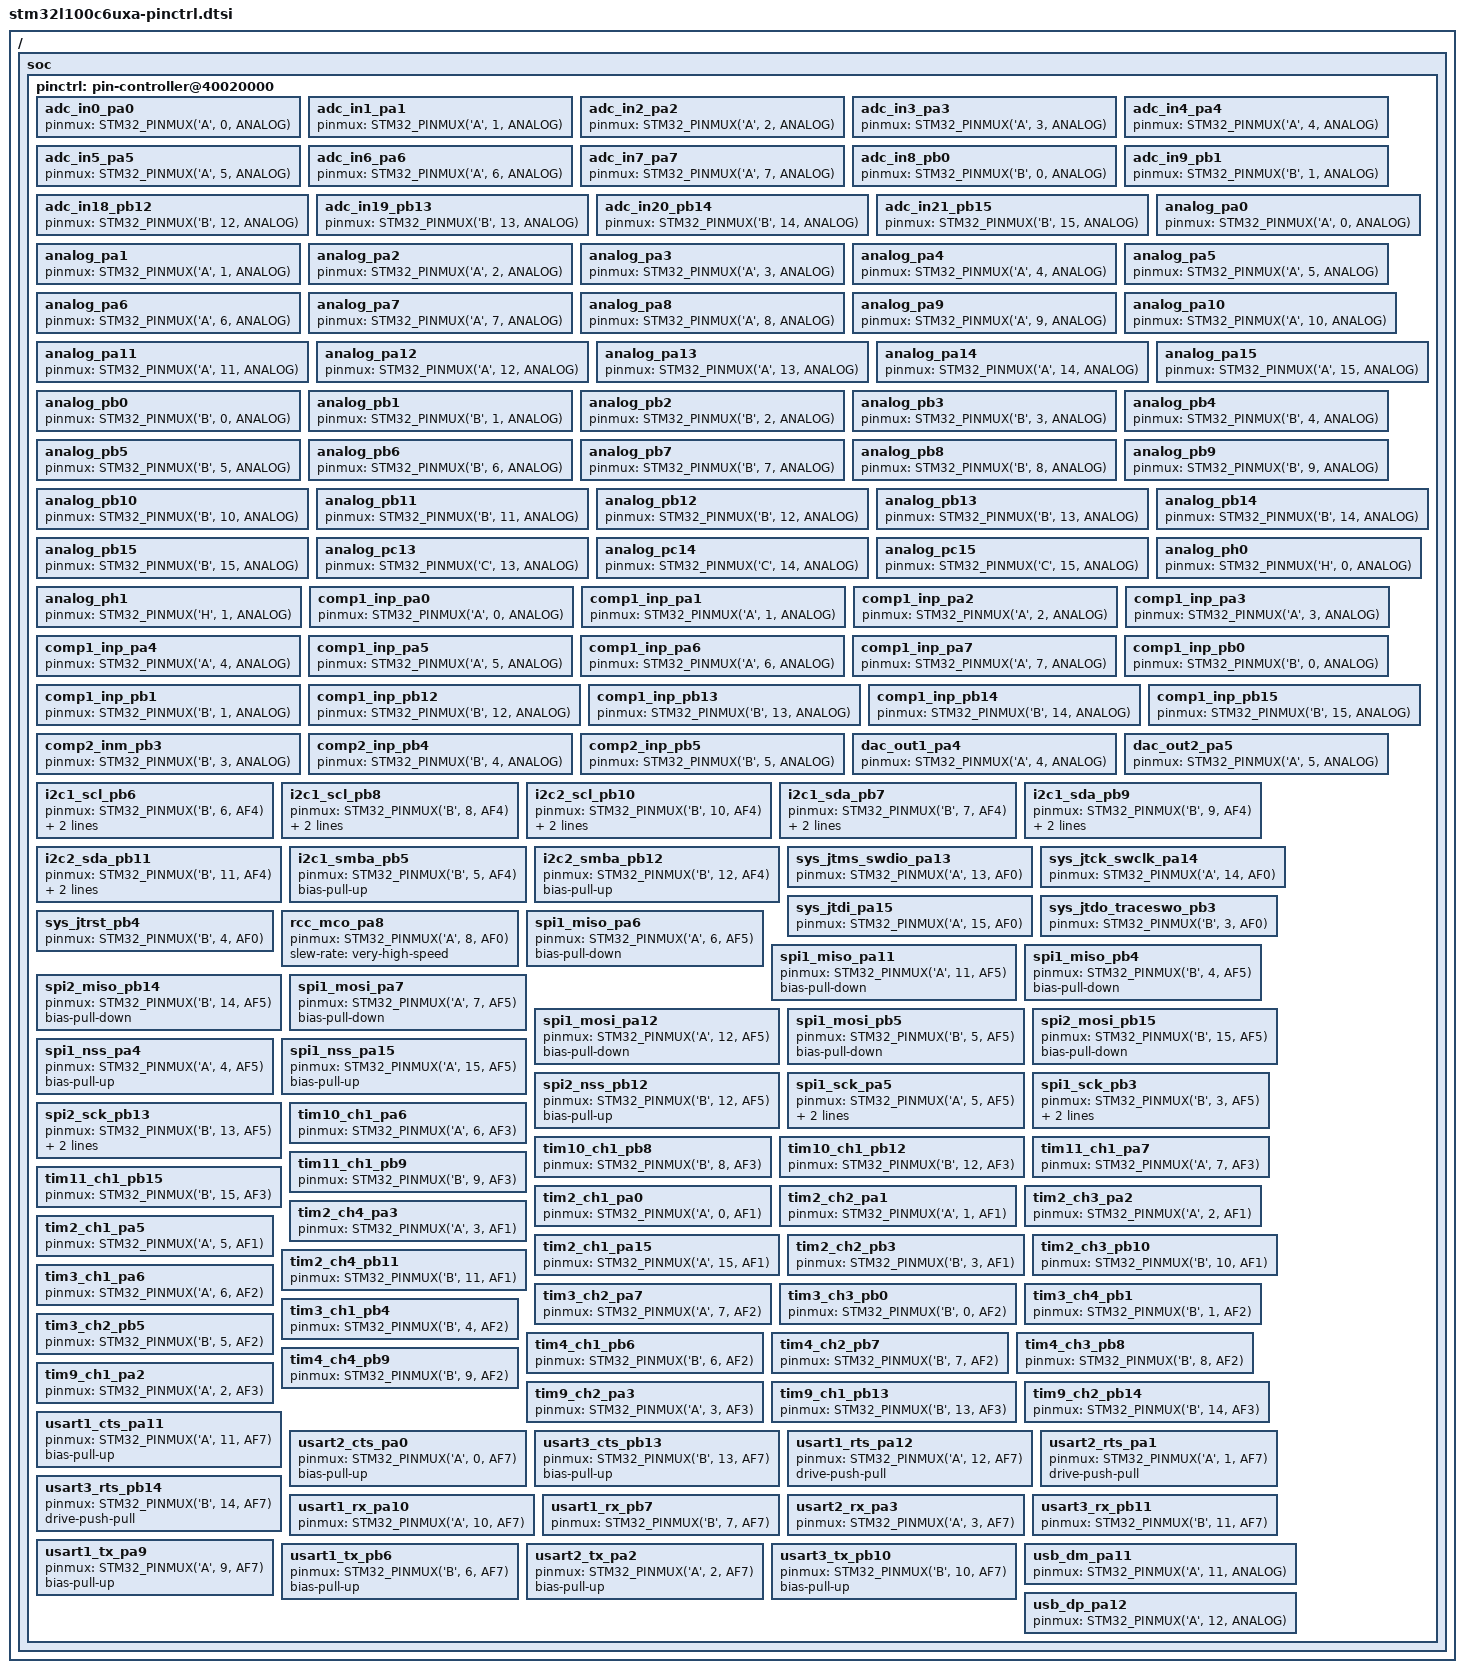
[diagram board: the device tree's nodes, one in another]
/*
 * NOTE: Autogenerated file using genpinctrl.py
 *
 * SPDX-License-Identifier: Apache-2.0
 */

#include <zephyr/dt-bindings/pinctrl/stm32-pinctrl.h>

/ {
	soc {
		pinctrl: pin-controller@40020000 {

			/* ADC_IN / ADC_INN / ADC_INP */

			/omit-if-no-ref/ adc_in0_pa0: adc_in0_pa0 {
				pinmux = <STM32_PINMUX('A', 0, ANALOG)>;
			};

			/omit-if-no-ref/ adc_in1_pa1: adc_in1_pa1 {
				pinmux = <STM32_PINMUX('A', 1, ANALOG)>;
			};

			/omit-if-no-ref/ adc_in2_pa2: adc_in2_pa2 {
				pinmux = <STM32_PINMUX('A', 2, ANALOG)>;
			};

			/omit-if-no-ref/ adc_in3_pa3: adc_in3_pa3 {
				pinmux = <STM32_PINMUX('A', 3, ANALOG)>;
			};

			/omit-if-no-ref/ adc_in4_pa4: adc_in4_pa4 {
				pinmux = <STM32_PINMUX('A', 4, ANALOG)>;
			};

			/omit-if-no-ref/ adc_in5_pa5: adc_in5_pa5 {
				pinmux = <STM32_PINMUX('A', 5, ANALOG)>;
			};

			/omit-if-no-ref/ adc_in6_pa6: adc_in6_pa6 {
				pinmux = <STM32_PINMUX('A', 6, ANALOG)>;
			};

			/omit-if-no-ref/ adc_in7_pa7: adc_in7_pa7 {
				pinmux = <STM32_PINMUX('A', 7, ANALOG)>;
			};

			/omit-if-no-ref/ adc_in8_pb0: adc_in8_pb0 {
				pinmux = <STM32_PINMUX('B', 0, ANALOG)>;
			};

			/omit-if-no-ref/ adc_in9_pb1: adc_in9_pb1 {
				pinmux = <STM32_PINMUX('B', 1, ANALOG)>;
			};

			/omit-if-no-ref/ adc_in18_pb12: adc_in18_pb12 {
				pinmux = <STM32_PINMUX('B', 12, ANALOG)>;
			};

			/omit-if-no-ref/ adc_in19_pb13: adc_in19_pb13 {
				pinmux = <STM32_PINMUX('B', 13, ANALOG)>;
			};

			/omit-if-no-ref/ adc_in20_pb14: adc_in20_pb14 {
				pinmux = <STM32_PINMUX('B', 14, ANALOG)>;
			};

			/omit-if-no-ref/ adc_in21_pb15: adc_in21_pb15 {
				pinmux = <STM32_PINMUX('B', 15, ANALOG)>;
			};

			/* Analog */

			/omit-if-no-ref/ analog_pa0: analog_pa0 {
				pinmux = <STM32_PINMUX('A', 0, ANALOG)>;
			};

			/omit-if-no-ref/ analog_pa1: analog_pa1 {
				pinmux = <STM32_PINMUX('A', 1, ANALOG)>;
			};

			/omit-if-no-ref/ analog_pa2: analog_pa2 {
				pinmux = <STM32_PINMUX('A', 2, ANALOG)>;
			};

			/omit-if-no-ref/ analog_pa3: analog_pa3 {
				pinmux = <STM32_PINMUX('A', 3, ANALOG)>;
			};

			/omit-if-no-ref/ analog_pa4: analog_pa4 {
				pinmux = <STM32_PINMUX('A', 4, ANALOG)>;
			};

			/omit-if-no-ref/ analog_pa5: analog_pa5 {
				pinmux = <STM32_PINMUX('A', 5, ANALOG)>;
			};

			/omit-if-no-ref/ analog_pa6: analog_pa6 {
				pinmux = <STM32_PINMUX('A', 6, ANALOG)>;
			};

			/omit-if-no-ref/ analog_pa7: analog_pa7 {
				pinmux = <STM32_PINMUX('A', 7, ANALOG)>;
			};

			/omit-if-no-ref/ analog_pa8: analog_pa8 {
				pinmux = <STM32_PINMUX('A', 8, ANALOG)>;
			};

			/omit-if-no-ref/ analog_pa9: analog_pa9 {
				pinmux = <STM32_PINMUX('A', 9, ANALOG)>;
			};

			/omit-if-no-ref/ analog_pa10: analog_pa10 {
				pinmux = <STM32_PINMUX('A', 10, ANALOG)>;
			};

			/omit-if-no-ref/ analog_pa11: analog_pa11 {
				pinmux = <STM32_PINMUX('A', 11, ANALOG)>;
			};

			/omit-if-no-ref/ analog_pa12: analog_pa12 {
				pinmux = <STM32_PINMUX('A', 12, ANALOG)>;
			};

			/omit-if-no-ref/ analog_pa13: analog_pa13 {
				pinmux = <STM32_PINMUX('A', 13, ANALOG)>;
			};

			/omit-if-no-ref/ analog_pa14: analog_pa14 {
				pinmux = <STM32_PINMUX('A', 14, ANALOG)>;
			};

			/omit-if-no-ref/ analog_pa15: analog_pa15 {
				pinmux = <STM32_PINMUX('A', 15, ANALOG)>;
			};

			/omit-if-no-ref/ analog_pb0: analog_pb0 {
				pinmux = <STM32_PINMUX('B', 0, ANALOG)>;
			};

			/omit-if-no-ref/ analog_pb1: analog_pb1 {
				pinmux = <STM32_PINMUX('B', 1, ANALOG)>;
			};

			/omit-if-no-ref/ analog_pb2: analog_pb2 {
				pinmux = <STM32_PINMUX('B', 2, ANALOG)>;
			};

			/omit-if-no-ref/ analog_pb3: analog_pb3 {
				pinmux = <STM32_PINMUX('B', 3, ANALOG)>;
			};

			/omit-if-no-ref/ analog_pb4: analog_pb4 {
				pinmux = <STM32_PINMUX('B', 4, ANALOG)>;
			};

			/omit-if-no-ref/ analog_pb5: analog_pb5 {
				pinmux = <STM32_PINMUX('B', 5, ANALOG)>;
			};

			/omit-if-no-ref/ analog_pb6: analog_pb6 {
				pinmux = <STM32_PINMUX('B', 6, ANALOG)>;
			};

			/omit-if-no-ref/ analog_pb7: analog_pb7 {
				pinmux = <STM32_PINMUX('B', 7, ANALOG)>;
			};

			/omit-if-no-ref/ analog_pb8: analog_pb8 {
				pinmux = <STM32_PINMUX('B', 8, ANALOG)>;
			};

			/omit-if-no-ref/ analog_pb9: analog_pb9 {
				pinmux = <STM32_PINMUX('B', 9, ANALOG)>;
			};

			/omit-if-no-ref/ analog_pb10: analog_pb10 {
				pinmux = <STM32_PINMUX('B', 10, ANALOG)>;
			};

			/omit-if-no-ref/ analog_pb11: analog_pb11 {
				pinmux = <STM32_PINMUX('B', 11, ANALOG)>;
			};

			/omit-if-no-ref/ analog_pb12: analog_pb12 {
				pinmux = <STM32_PINMUX('B', 12, ANALOG)>;
			};

			/omit-if-no-ref/ analog_pb13: analog_pb13 {
				pinmux = <STM32_PINMUX('B', 13, ANALOG)>;
			};

			/omit-if-no-ref/ analog_pb14: analog_pb14 {
				pinmux = <STM32_PINMUX('B', 14, ANALOG)>;
			};

			/omit-if-no-ref/ analog_pb15: analog_pb15 {
				pinmux = <STM32_PINMUX('B', 15, ANALOG)>;
			};

			/omit-if-no-ref/ analog_pc13: analog_pc13 {
				pinmux = <STM32_PINMUX('C', 13, ANALOG)>;
			};

			/omit-if-no-ref/ analog_pc14: analog_pc14 {
				pinmux = <STM32_PINMUX('C', 14, ANALOG)>;
			};

			/omit-if-no-ref/ analog_pc15: analog_pc15 {
				pinmux = <STM32_PINMUX('C', 15, ANALOG)>;
			};

			/omit-if-no-ref/ analog_ph0: analog_ph0 {
				pinmux = <STM32_PINMUX('H', 0, ANALOG)>;
			};

			/omit-if-no-ref/ analog_ph1: analog_ph1 {
				pinmux = <STM32_PINMUX('H', 1, ANALOG)>;
			};

			/* COMP_IN */

			/omit-if-no-ref/ comp1_inp_pa0: comp1_inp_pa0 {
				pinmux = <STM32_PINMUX('A', 0, ANALOG)>;
			};

			/omit-if-no-ref/ comp1_inp_pa1: comp1_inp_pa1 {
				pinmux = <STM32_PINMUX('A', 1, ANALOG)>;
			};

			/omit-if-no-ref/ comp1_inp_pa2: comp1_inp_pa2 {
				pinmux = <STM32_PINMUX('A', 2, ANALOG)>;
			};

			/omit-if-no-ref/ comp1_inp_pa3: comp1_inp_pa3 {
				pinmux = <STM32_PINMUX('A', 3, ANALOG)>;
			};

			/omit-if-no-ref/ comp1_inp_pa4: comp1_inp_pa4 {
				pinmux = <STM32_PINMUX('A', 4, ANALOG)>;
			};

			/omit-if-no-ref/ comp1_inp_pa5: comp1_inp_pa5 {
				pinmux = <STM32_PINMUX('A', 5, ANALOG)>;
			};

			/omit-if-no-ref/ comp1_inp_pa6: comp1_inp_pa6 {
				pinmux = <STM32_PINMUX('A', 6, ANALOG)>;
			};

			/omit-if-no-ref/ comp1_inp_pa7: comp1_inp_pa7 {
				pinmux = <STM32_PINMUX('A', 7, ANALOG)>;
			};

			/omit-if-no-ref/ comp1_inp_pb0: comp1_inp_pb0 {
				pinmux = <STM32_PINMUX('B', 0, ANALOG)>;
			};

			/omit-if-no-ref/ comp1_inp_pb1: comp1_inp_pb1 {
				pinmux = <STM32_PINMUX('B', 1, ANALOG)>;
			};

			/omit-if-no-ref/ comp1_inp_pb12: comp1_inp_pb12 {
				pinmux = <STM32_PINMUX('B', 12, ANALOG)>;
			};

			/omit-if-no-ref/ comp1_inp_pb13: comp1_inp_pb13 {
				pinmux = <STM32_PINMUX('B', 13, ANALOG)>;
			};

			/omit-if-no-ref/ comp1_inp_pb14: comp1_inp_pb14 {
				pinmux = <STM32_PINMUX('B', 14, ANALOG)>;
			};

			/omit-if-no-ref/ comp1_inp_pb15: comp1_inp_pb15 {
				pinmux = <STM32_PINMUX('B', 15, ANALOG)>;
			};

			/omit-if-no-ref/ comp2_inm_pb3: comp2_inm_pb3 {
				pinmux = <STM32_PINMUX('B', 3, ANALOG)>;
			};

			/omit-if-no-ref/ comp2_inp_pb4: comp2_inp_pb4 {
				pinmux = <STM32_PINMUX('B', 4, ANALOG)>;
			};

			/omit-if-no-ref/ comp2_inp_pb5: comp2_inp_pb5 {
				pinmux = <STM32_PINMUX('B', 5, ANALOG)>;
			};

			/* DAC_OUT */

			/omit-if-no-ref/ dac_out1_pa4: dac_out1_pa4 {
				pinmux = <STM32_PINMUX('A', 4, ANALOG)>;
			};

			/omit-if-no-ref/ dac_out2_pa5: dac_out2_pa5 {
				pinmux = <STM32_PINMUX('A', 5, ANALOG)>;
			};

			/* I2C_SCL */

			/omit-if-no-ref/ i2c1_scl_pb6: i2c1_scl_pb6 {
				pinmux = <STM32_PINMUX('B', 6, AF4)>;
				bias-pull-up;
				drive-open-drain;
			};

			/omit-if-no-ref/ i2c1_scl_pb8: i2c1_scl_pb8 {
				pinmux = <STM32_PINMUX('B', 8, AF4)>;
				bias-pull-up;
				drive-open-drain;
			};

			/omit-if-no-ref/ i2c2_scl_pb10: i2c2_scl_pb10 {
				pinmux = <STM32_PINMUX('B', 10, AF4)>;
				bias-pull-up;
				drive-open-drain;
			};

			/* I2C_SDA */

			/omit-if-no-ref/ i2c1_sda_pb7: i2c1_sda_pb7 {
				pinmux = <STM32_PINMUX('B', 7, AF4)>;
				bias-pull-up;
				drive-open-drain;
			};

			/omit-if-no-ref/ i2c1_sda_pb9: i2c1_sda_pb9 {
				pinmux = <STM32_PINMUX('B', 9, AF4)>;
				bias-pull-up;
				drive-open-drain;
			};

			/omit-if-no-ref/ i2c2_sda_pb11: i2c2_sda_pb11 {
				pinmux = <STM32_PINMUX('B', 11, AF4)>;
				bias-pull-up;
				drive-open-drain;
			};

			/* I2C_SMBA */

			/omit-if-no-ref/ i2c1_smba_pb5: i2c1_smba_pb5 {
				pinmux = <STM32_PINMUX('B', 5, AF4)>;
				bias-pull-up;
			};

			/omit-if-no-ref/ i2c2_smba_pb12: i2c2_smba_pb12 {
				pinmux = <STM32_PINMUX('B', 12, AF4)>;
				bias-pull-up;
			};

			/* JTAG PORT */

			/omit-if-no-ref/ sys_jtms_swdio_pa13: sys_jtms_swdio_pa13 {
				pinmux = <STM32_PINMUX('A', 13, AF0)>;
			};

			/omit-if-no-ref/ sys_jtck_swclk_pa14: sys_jtck_swclk_pa14 {
				pinmux = <STM32_PINMUX('A', 14, AF0)>;
			};

			/omit-if-no-ref/ sys_jtdi_pa15: sys_jtdi_pa15 {
				pinmux = <STM32_PINMUX('A', 15, AF0)>;
			};

			/omit-if-no-ref/ sys_jtdo_traceswo_pb3: sys_jtdo_traceswo_pb3 {
				pinmux = <STM32_PINMUX('B', 3, AF0)>;
			};

			/omit-if-no-ref/ sys_jtrst_pb4: sys_jtrst_pb4 {
				pinmux = <STM32_PINMUX('B', 4, AF0)>;
			};

			/* RCC_MCO */

			/omit-if-no-ref/ rcc_mco_pa8: rcc_mco_pa8 {
				pinmux = <STM32_PINMUX('A', 8, AF0)>;
				slew-rate = "very-high-speed";
			};

			/* SPI_MISO */

			/omit-if-no-ref/ spi1_miso_pa6: spi1_miso_pa6 {
				pinmux = <STM32_PINMUX('A', 6, AF5)>;
				bias-pull-down;
			};

			/omit-if-no-ref/ spi1_miso_pa11: spi1_miso_pa11 {
				pinmux = <STM32_PINMUX('A', 11, AF5)>;
				bias-pull-down;
			};

			/omit-if-no-ref/ spi1_miso_pb4: spi1_miso_pb4 {
				pinmux = <STM32_PINMUX('B', 4, AF5)>;
				bias-pull-down;
			};

			/omit-if-no-ref/ spi2_miso_pb14: spi2_miso_pb14 {
				pinmux = <STM32_PINMUX('B', 14, AF5)>;
				bias-pull-down;
			};

			/* SPI_MOSI */

			/omit-if-no-ref/ spi1_mosi_pa7: spi1_mosi_pa7 {
				pinmux = <STM32_PINMUX('A', 7, AF5)>;
				bias-pull-down;
			};

			/omit-if-no-ref/ spi1_mosi_pa12: spi1_mosi_pa12 {
				pinmux = <STM32_PINMUX('A', 12, AF5)>;
				bias-pull-down;
			};

			/omit-if-no-ref/ spi1_mosi_pb5: spi1_mosi_pb5 {
				pinmux = <STM32_PINMUX('B', 5, AF5)>;
				bias-pull-down;
			};

			/omit-if-no-ref/ spi2_mosi_pb15: spi2_mosi_pb15 {
				pinmux = <STM32_PINMUX('B', 15, AF5)>;
				bias-pull-down;
			};

			/* SPI_NSS */

			/omit-if-no-ref/ spi1_nss_pa4: spi1_nss_pa4 {
				pinmux = <STM32_PINMUX('A', 4, AF5)>;
				bias-pull-up;
			};

			/omit-if-no-ref/ spi1_nss_pa15: spi1_nss_pa15 {
				pinmux = <STM32_PINMUX('A', 15, AF5)>;
				bias-pull-up;
			};

			/omit-if-no-ref/ spi2_nss_pb12: spi2_nss_pb12 {
				pinmux = <STM32_PINMUX('B', 12, AF5)>;
				bias-pull-up;
			};

			/* SPI_SCK */

			/omit-if-no-ref/ spi1_sck_pa5: spi1_sck_pa5 {
				pinmux = <STM32_PINMUX('A', 5, AF5)>;
				bias-pull-down;
				slew-rate = "very-high-speed";
			};

			/omit-if-no-ref/ spi1_sck_pb3: spi1_sck_pb3 {
				pinmux = <STM32_PINMUX('B', 3, AF5)>;
				bias-pull-down;
				slew-rate = "very-high-speed";
			};

			/omit-if-no-ref/ spi2_sck_pb13: spi2_sck_pb13 {
				pinmux = <STM32_PINMUX('B', 13, AF5)>;
				bias-pull-down;
				slew-rate = "very-high-speed";
			};

			/* TIM_CH / TIM_CHN */

			/omit-if-no-ref/ tim10_ch1_pa6: tim10_ch1_pa6 {
				pinmux = <STM32_PINMUX('A', 6, AF3)>;
			};

			/omit-if-no-ref/ tim10_ch1_pb8: tim10_ch1_pb8 {
				pinmux = <STM32_PINMUX('B', 8, AF3)>;
			};

			/omit-if-no-ref/ tim10_ch1_pb12: tim10_ch1_pb12 {
				pinmux = <STM32_PINMUX('B', 12, AF3)>;
			};

			/omit-if-no-ref/ tim11_ch1_pa7: tim11_ch1_pa7 {
				pinmux = <STM32_PINMUX('A', 7, AF3)>;
			};

			/omit-if-no-ref/ tim11_ch1_pb9: tim11_ch1_pb9 {
				pinmux = <STM32_PINMUX('B', 9, AF3)>;
			};

			/omit-if-no-ref/ tim11_ch1_pb15: tim11_ch1_pb15 {
				pinmux = <STM32_PINMUX('B', 15, AF3)>;
			};

			/omit-if-no-ref/ tim2_ch1_pa0: tim2_ch1_pa0 {
				pinmux = <STM32_PINMUX('A', 0, AF1)>;
			};

			/omit-if-no-ref/ tim2_ch2_pa1: tim2_ch2_pa1 {
				pinmux = <STM32_PINMUX('A', 1, AF1)>;
			};

			/omit-if-no-ref/ tim2_ch3_pa2: tim2_ch3_pa2 {
				pinmux = <STM32_PINMUX('A', 2, AF1)>;
			};

			/omit-if-no-ref/ tim2_ch4_pa3: tim2_ch4_pa3 {
				pinmux = <STM32_PINMUX('A', 3, AF1)>;
			};

			/omit-if-no-ref/ tim2_ch1_pa5: tim2_ch1_pa5 {
				pinmux = <STM32_PINMUX('A', 5, AF1)>;
			};

			/omit-if-no-ref/ tim2_ch1_pa15: tim2_ch1_pa15 {
				pinmux = <STM32_PINMUX('A', 15, AF1)>;
			};

			/omit-if-no-ref/ tim2_ch2_pb3: tim2_ch2_pb3 {
				pinmux = <STM32_PINMUX('B', 3, AF1)>;
			};

			/omit-if-no-ref/ tim2_ch3_pb10: tim2_ch3_pb10 {
				pinmux = <STM32_PINMUX('B', 10, AF1)>;
			};

			/omit-if-no-ref/ tim2_ch4_pb11: tim2_ch4_pb11 {
				pinmux = <STM32_PINMUX('B', 11, AF1)>;
			};

			/omit-if-no-ref/ tim3_ch1_pa6: tim3_ch1_pa6 {
				pinmux = <STM32_PINMUX('A', 6, AF2)>;
			};

			/omit-if-no-ref/ tim3_ch2_pa7: tim3_ch2_pa7 {
				pinmux = <STM32_PINMUX('A', 7, AF2)>;
			};

			/omit-if-no-ref/ tim3_ch3_pb0: tim3_ch3_pb0 {
				pinmux = <STM32_PINMUX('B', 0, AF2)>;
			};

			/omit-if-no-ref/ tim3_ch4_pb1: tim3_ch4_pb1 {
				pinmux = <STM32_PINMUX('B', 1, AF2)>;
			};

			/omit-if-no-ref/ tim3_ch1_pb4: tim3_ch1_pb4 {
				pinmux = <STM32_PINMUX('B', 4, AF2)>;
			};

			/omit-if-no-ref/ tim3_ch2_pb5: tim3_ch2_pb5 {
				pinmux = <STM32_PINMUX('B', 5, AF2)>;
			};

			/omit-if-no-ref/ tim4_ch1_pb6: tim4_ch1_pb6 {
				pinmux = <STM32_PINMUX('B', 6, AF2)>;
			};

			/omit-if-no-ref/ tim4_ch2_pb7: tim4_ch2_pb7 {
				pinmux = <STM32_PINMUX('B', 7, AF2)>;
			};

			/omit-if-no-ref/ tim4_ch3_pb8: tim4_ch3_pb8 {
				pinmux = <STM32_PINMUX('B', 8, AF2)>;
			};

			/omit-if-no-ref/ tim4_ch4_pb9: tim4_ch4_pb9 {
				pinmux = <STM32_PINMUX('B', 9, AF2)>;
			};

			/omit-if-no-ref/ tim9_ch1_pa2: tim9_ch1_pa2 {
				pinmux = <STM32_PINMUX('A', 2, AF3)>;
			};

			/omit-if-no-ref/ tim9_ch2_pa3: tim9_ch2_pa3 {
				pinmux = <STM32_PINMUX('A', 3, AF3)>;
			};

			/omit-if-no-ref/ tim9_ch1_pb13: tim9_ch1_pb13 {
				pinmux = <STM32_PINMUX('B', 13, AF3)>;
			};

			/omit-if-no-ref/ tim9_ch2_pb14: tim9_ch2_pb14 {
				pinmux = <STM32_PINMUX('B', 14, AF3)>;
			};

			/* UART_CTS / USART_CTS / LPUART_CTS */

			/omit-if-no-ref/ usart1_cts_pa11: usart1_cts_pa11 {
				pinmux = <STM32_PINMUX('A', 11, AF7)>;
				bias-pull-up;
			};

			/omit-if-no-ref/ usart2_cts_pa0: usart2_cts_pa0 {
				pinmux = <STM32_PINMUX('A', 0, AF7)>;
				bias-pull-up;
			};

			/omit-if-no-ref/ usart3_cts_pb13: usart3_cts_pb13 {
				pinmux = <STM32_PINMUX('B', 13, AF7)>;
				bias-pull-up;
			};

			/* UART_RTS / USART_RTS / LPUART_RTS */

			/omit-if-no-ref/ usart1_rts_pa12: usart1_rts_pa12 {
				pinmux = <STM32_PINMUX('A', 12, AF7)>;
				drive-push-pull;
			};

			/omit-if-no-ref/ usart2_rts_pa1: usart2_rts_pa1 {
				pinmux = <STM32_PINMUX('A', 1, AF7)>;
				drive-push-pull;
			};

			/omit-if-no-ref/ usart3_rts_pb14: usart3_rts_pb14 {
				pinmux = <STM32_PINMUX('B', 14, AF7)>;
				drive-push-pull;
			};

			/* UART_RX / USART_RX / LPUART_RX */

			/omit-if-no-ref/ usart1_rx_pa10: usart1_rx_pa10 {
				pinmux = <STM32_PINMUX('A', 10, AF7)>;
			};

			/omit-if-no-ref/ usart1_rx_pb7: usart1_rx_pb7 {
				pinmux = <STM32_PINMUX('B', 7, AF7)>;
			};

			/omit-if-no-ref/ usart2_rx_pa3: usart2_rx_pa3 {
				pinmux = <STM32_PINMUX('A', 3, AF7)>;
			};

			/omit-if-no-ref/ usart3_rx_pb11: usart3_rx_pb11 {
				pinmux = <STM32_PINMUX('B', 11, AF7)>;
			};

			/* UART_TX / USART_TX / LPUART_TX */

			/omit-if-no-ref/ usart1_tx_pa9: usart1_tx_pa9 {
				pinmux = <STM32_PINMUX('A', 9, AF7)>;
				bias-pull-up;
			};

			/omit-if-no-ref/ usart1_tx_pb6: usart1_tx_pb6 {
				pinmux = <STM32_PINMUX('B', 6, AF7)>;
				bias-pull-up;
			};

			/omit-if-no-ref/ usart2_tx_pa2: usart2_tx_pa2 {
				pinmux = <STM32_PINMUX('A', 2, AF7)>;
				bias-pull-up;
			};

			/omit-if-no-ref/ usart3_tx_pb10: usart3_tx_pb10 {
				pinmux = <STM32_PINMUX('B', 10, AF7)>;
				bias-pull-up;
			};

			/* USB */

			/omit-if-no-ref/ usb_dm_pa11: usb_dm_pa11 {
				pinmux = <STM32_PINMUX('A', 11, ANALOG)>;
			};

			/omit-if-no-ref/ usb_dp_pa12: usb_dp_pa12 {
				pinmux = <STM32_PINMUX('A', 12, ANALOG)>;
			};

		};
	};
};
